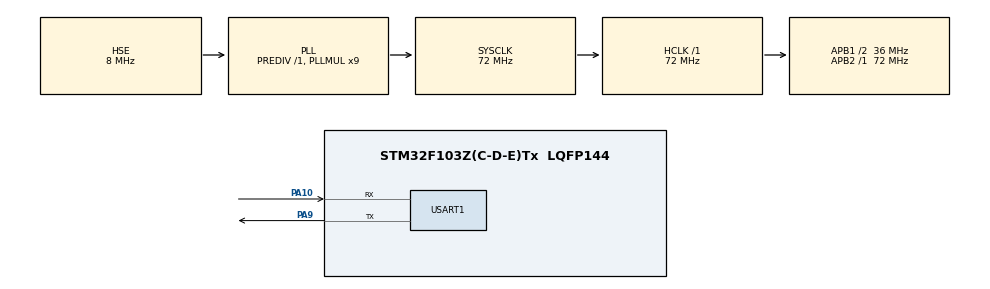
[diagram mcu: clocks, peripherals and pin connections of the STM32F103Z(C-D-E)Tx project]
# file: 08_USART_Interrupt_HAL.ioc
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Mcu.Family=STM32F1
Mcu.Name=STM32F103Z(C-D-E)Tx
Mcu.Package=LQFP144
NVIC.PriorityGroup=NVIC_PRIORITYGROUP_4
NVIC.USART1_IRQn=true\:0\:0\:false\:false\:true\:true\:true\:true
OSC_IN.Mode=HSE-External-Oscillator
OSC_IN.Signal=RCC_OSC_IN
OSC_OUT.Mode=HSE-External-Oscillator
OSC_OUT.Signal=RCC_OSC_OUT
PA10.Mode=Asynchronous
PA10.Signal=USART1_RX
PA13.Mode=Serial_Wire
PA13.Signal=SYS_JTMS-SWDIO
PA14.Mode=Serial_Wire
PA14.Signal=SYS_JTCK-SWCLK
PA9.Mode=Asynchronous
PA9.Signal=USART1_TX
PC14-OSC32_IN.Mode=LSE-External-Oscillator
PC14-OSC32_IN.Signal=RCC_OSC32_IN
PC15-OSC32_OUT.Mode=LSE-External-Oscillator
PC15-OSC32_OUT.Signal=RCC_OSC32_OUT
ProjectManager.HeapSize=0x200
ProjectManager.StackSize=0x400
ProjectManager.TargetToolchain=MDK-ARM V5.32
RCC.AHBFreq_Value=72000000
RCC.APB1CLKDivider=RCC_HCLK_DIV2
RCC.APB1Freq_Value=36000000
RCC.APB1TimFreq_Value=72000000
RCC.APB2Freq_Value=72000000
RCC.APB2TimFreq_Value=72000000
RCC.HCLKFreq_Value=72000000
RCC.PLLMUL=RCC_PLL_MUL9
RCC.PLLSourceVirtual=RCC_PLLSOURCE_HSE
RCC.SYSCLKFreq_VALUE=72000000
RCC.SYSCLKSource=RCC_SYSCLKSOURCE_PLLCLK
RCC.USBFreq_Value=72000000
USART1.VirtualMode=VM_ASYNC
board=custom

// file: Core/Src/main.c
/* USER CODE BEGIN Header */
/**
  ******************************************************************************
  * @file           : main.c
  * @brief          : Main program body
  ******************************************************************************
  * @attention
  *
  * Copyright (c) 2025 STMicroelectronics.
  * All rights reserved.
  *
  * This software is licensed under terms that can be found in the LICENSE file
  * in the root directory of this software component.
  * If no LICENSE file comes with this software, it is provided AS-IS.
  *
  ******************************************************************************
  */
/* USER CODE END Header */
#include "main.h"
#include "usart.h"
#include "gpio.h"

void SystemClock_Config(void);

/* USER CODE BEGIN 0 */
uint8_t buff[100]={0};
//接收完成回调函数
void HAL_UART_RxCpltCallback(UART_HandleTypeDef *huart){
   HAL_UART_Transmit(&huart1,buff,3,1000);

   //这个接收中断方法只执行一次后中断关闭，想继续执行，必须重新调用
   HAL_UART_Receive_IT(&huart1,buff,3);
}
/* USER CODE END 0 */

int main(void)
{

  /* MCU Configuration--------------------------------------------------------*/

  /* Reset of all peripherals, Initializes the Flash interface and the Systick. */
  HAL_Init();

  /* Configure the system clock */
  SystemClock_Config();

  /* Initialize all configured peripherals */
  MX_GPIO_Init();
  MX_USART1_UART_Init();

  /* Infinite loop */
  /* USER CODE BEGIN WHILE */
  /**
   * @brief 发送一个字符串
   * 三种方式
   * HAL_UART_Transmit/DMA/IT
   * 传结构体指针和结构体变量的区别：传结构体变量是把结构体复制一份传过去，适合结构体数据量比较小的
   * 结构体，传结构体指针访问的是同一个结构体
   */
  uint8_t* str="You are success!";
  uint16_t len =strlen(str);
  uint32_t timeOut=1000;
  HAL_UART_Transmit(&huart1,str,len,timeOut);

  /**
   * @brief 中断的方式接收数据
   * void USART1_IRHandler(void) 这个中断函数每接收一个字符会执行一次
   * HAL_UART_Receive_IT(&huart1,str,len); 使用中断的方式接收数据，接收到的数据存放在buff中，
   *   当接收到len长度的字节，会执行接收完成的回调函数
   * void HAL_UART_RxCpltCallback(UART_HandleTypeDef *huart) 接收完成回调函数
   *
   * HAL_UART_Receive_IT 这个函数只接收一次，接收一次完成以后这个中断就关闭了，如果还想继续，把这个调用
   * 函数放到回调函数中
   *
   * 这种方式就是每次只能发送固定长度的字符串，如果发送的字符串长度超过固定长度会出现问题
   * 可以在main.c这个文件中Error_Handler() 函数中写自定义代码查看错误信息
   *
   * 总结：这种中断方式只能接收固定长度的字符串，少发会一直在等，多发会出问题
   */
  HAL_UART_Receive_IT(&huart1,buff,3);
  while (1)
  {
    /* USER CODE END WHILE */

  }
}

void SystemClock_Config(void)
{
  RCC_OscInitTypeDef RCC_OscInitStruct = {0};
  RCC_ClkInitTypeDef RCC_ClkInitStruct = {0};

  /** Initializes the RCC Oscillators according to the specified parameters
  * in the RCC_OscInitTypeDef structure.
  */
  RCC_OscInitStruct.OscillatorType = RCC_OSCILLATORTYPE_HSE;
  RCC_OscInitStruct.HSEState = RCC_HSE_ON;
  RCC_OscInitStruct.HSEPredivValue = RCC_HSE_PREDIV_DIV1;
  RCC_OscInitStruct.HSIState = RCC_HSI_ON;
  RCC_OscInitStruct.PLL.PLLState = RCC_PLL_ON;
  RCC_OscInitStruct.PLL.PLLSource = RCC_PLLSOURCE_HSE;
  RCC_OscInitStruct.PLL.PLLMUL = RCC_PLL_MUL9;
  if (HAL_RCC_OscConfig(&RCC_OscInitStruct) != HAL_OK)
  {
    Error_Handler();
  }

  /** Initializes the CPU, AHB and APB buses clocks
  */
  RCC_ClkInitStruct.ClockType = RCC_CLOCKTYPE_HCLK|RCC_CLOCKTYPE_SYSCLK
                              |RCC_CLOCKTYPE_PCLK1|RCC_CLOCKTYPE_PCLK2;
  RCC_ClkInitStruct.SYSCLKSource = RCC_SYSCLKSOURCE_PLLCLK;
  RCC_ClkInitStruct.AHBCLKDivider = RCC_SYSCLK_DIV1;
  RCC_ClkInitStruct.APB1CLKDivider = RCC_HCLK_DIV2;
  RCC_ClkInitStruct.APB2CLKDivider = RCC_HCLK_DIV1;

  if (HAL_RCC_ClockConfig(&RCC_ClkInitStruct, FLASH_LATENCY_2) != HAL_OK)
  {
    Error_Handler();
  }
}

void Error_Handler(void)
{
  __disable_irq();
  while (1)
  {
  }
}
